# DSC28027 register map
Vendor: Beijing Haawking Technology Co.,Ltd.; File version: 1.0
Registers are 32-bit, read-write, reset 0x0 unless marked. A register's access mark holds for its fields unless they carry their own. Offsets are from the block's base; [hi:lo] are bit positions; lines under a group give offsets from that group; {n}, {i} and the like mark numbered series; 'fields as' and 'values as' point back to an identical list.

## DMAC — Direct Memory Access Controller
Base 0x50000000
0x00 id 64-bit (reset mask 0xFFFFFFFF)
0x08 compver 64-bit (reset mask 0xFFFFFFFF)
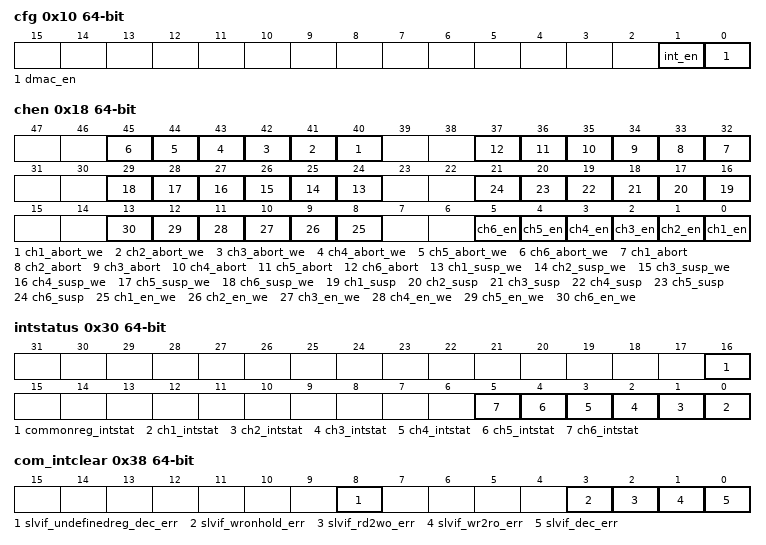
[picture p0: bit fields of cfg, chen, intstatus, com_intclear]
0x10 cfg 64-bit — Configure Register
  [1] int_en — Globally enable interrupt generation
  [0] dmac_en — Enable DMAC
0x18 chen 64-bit (reset mask 0xFFFFFFFF) — Channel Enable Register
  [n+39] ch{n}_abort_we (n=1..6) — Enable write to ch{n}_abort bit
  [n+31] ch{n}_abort (n=1..6) — Abort request channel {n}
  [n+23] ch{n}_susp_we (n=1..6) — Enable write to ch{n}_susp bit
  [n+15] ch{n}_susp (n=1..6) — Suspend request channel {n}
  [n+7] ch{n}_en_we (n=1..6) — Write enable channel {n}
  [n-1] ch{n}_en (n=1..6) — Enable channel {n}
0x30 intstatus 64-bit (reset mask 0xFFFFFFFF) — Interrupt Status Register
  [16] commonreg_intstat — Common register status bit
  [n-1] ch{n}_intstat (n=1..6) — Channel {n} interrupt bit
0x38 com_intclear 64-bit — Common Interrupt Clear Register
  [8] slvif_undefinedreg_dec_err — Clear slvif_undefinedreg_dec_err in com_intstatus
  [3] slvif_wronhold_err — Clear slvif_wronhold_err interrupt in com_intstatus
  [2] slvif_rd2wo_err — Clear slvif_rd2wo_err interrupt in com_intstatus
  [1] slvif_wr2ro_err — Clear slvif_wr2ro_err interrupt in com_intstatus
  [0] slvif_dec_err — Clear slvif_dec_err interrupt in com_intstatus
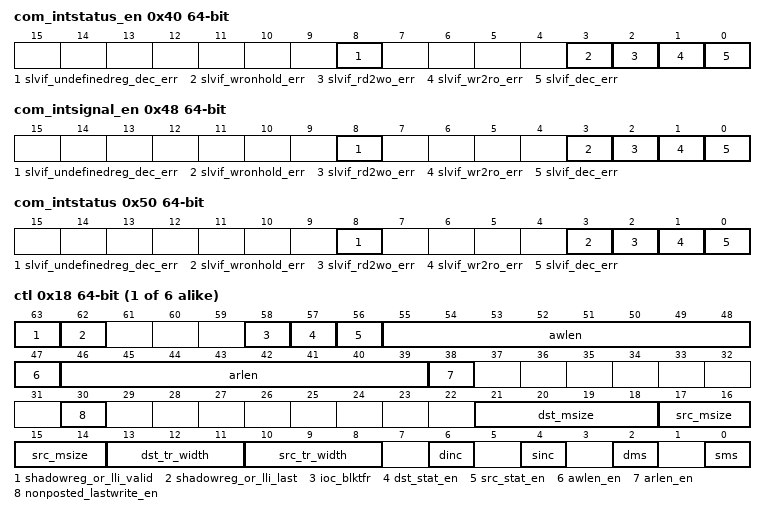
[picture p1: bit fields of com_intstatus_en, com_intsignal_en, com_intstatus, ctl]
0x40 com_intstatus_en 64-bit — Common Interrupt Status Enable Register
  [8] slvif_undefinedreg_dec_err — Slave Interface Undefined Register Decode Error
  [3] slvif_wronhold_err — Slave Interface Common Register Write On Hold Error
  [2] slvif_rd2wo_err — Slave Interface Common Register Read to Write-only Error
  [1] slvif_wr2ro_err — Slave Interface Common Register Write to Read only Error
  [0] slvif_dec_err — Slave Interface Common Register Decode Error
0x48 com_intsignal_en 64-bit — Common Interrupt Signal Enable Register
  fields as com_intstatus_en
0x50 com_intstatus 64-bit — Common Interrupt Status
  fields as com_intstatus_en
0x58 reset 64-bit
  [0] rst — DMAC reset request bit
{0x100+0x100*i} channel[{i}] (i=0..5) group — Channel configuration
  0x00 sar 64-bit (reset mask 0xFFFFFFFF) — SAR Address Register
  0x08 dar 64-bit (reset mask 0xFFFFFFFF) — DAR Address Register
  0x10 block_ts 64-bit — Block Transfer Size Register
    [21:0] block_ts — Block transfer size
  0x18 ctl 64-bit (reset mask 0xFFFFFFFF) — Control Register
    [63] shadowreg_or_lli_valid — last shadow linked list item valid (indicate shadowreg/LLI content is valid)
    [62] shadowreg_or_lli_last — Last shadow linked list item (indicates shadowreg/LLI content is the last one)
    [58] ioc_blktfr — Interrupt completion of block transfer
    [57] dst_stat_en — Destination status enable
    [56] src_stat_en — Source status enable
    [55:48] awlen — Destination burst length
    [47] awlen_en — Destination burst length enable
    [46:39] arlen — Source burst length
    [38] arlen_en — Source burst length enable
    [30] nonposted_lastwrite_en — Non Posted Last Write Enable (posted writes may be used till the end of the block)
    [21:18] dst_msize — Destination burst transaction length
      0=length_1 (1 data item); 1=length_4 (4 data items); 2=length_8 (8 data items); 3=length_16 (16 data items); 4=length_32 (32 data items); 5=length_64 (64 data items); 6=length_128 (128 data items); 7=length_256 (256 data items); 8=length_512 (512 data items); 9=length_1024 (1024 data items)
    [17:14] src_msize — Source burst transaction length
      values as dst_msize
    [13:11] dst_tr_width — Destination transfer width
      0=width_8 (8 bits); 1=width_16 (16 bits); 2=width_32 (32 bits); 3=width_64 (64 bits); 4=width_128 (128 bits); 5=width_256 (256 bits); 6=width_512 (512 bits)
    [10:8] src_tr_width — Source transfer width
      values as dst_tr_width
    [6] dinc — Destination address increment
      0=Increment address; 1=nochange (Don't increment address)
    [4] sinc — Source address increment
      0=Increment address; 1=nochange (Don't increment address)
    [2] dms — Destination master select
      0=axi_master_1; 1=axi_master_2
    [0] sms — Source master select
      0=axi_master_1; 1=axi_master_2
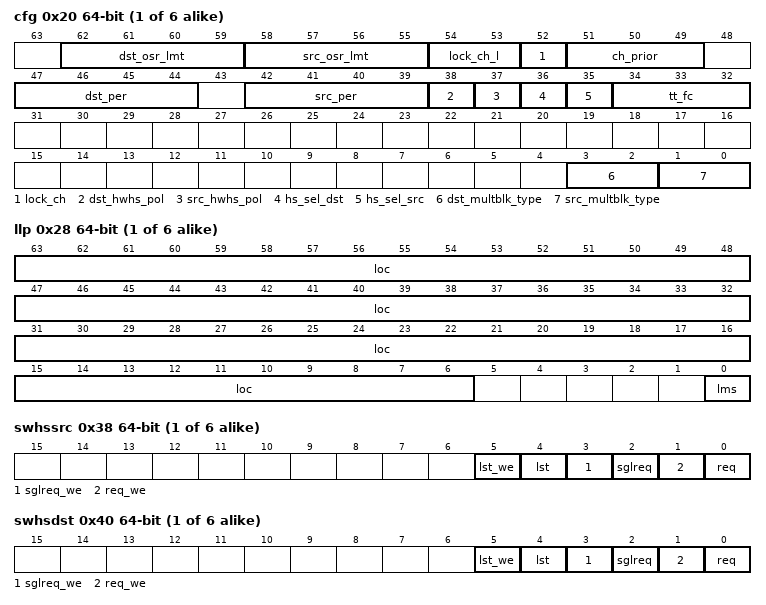
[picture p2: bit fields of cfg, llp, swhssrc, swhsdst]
  0x20 cfg 64-bit (reset mask 0xFFFFFFFF) — Configure Register
    [62:59] dst_osr_lmt — Destination outstanding request limit
    [58:55] src_osr_lmt — Source outstanding request limit
    [54:53] lock_ch_l — Channel lock level
      0=dma_transfer (Duration of channel is locked for entire DMA transfer); 1=block_transfer (Duration of channel is locked for current block transfer); 2=transaction (Duration of channel is locked for current transaction)
    [52] lock_ch — Channel lock bit
    [51:49] ch_prior — Channel priority (7 is highest, 0 is lowest)
    [47:44] dst_per — Assign a hardware handshaking interface to destination of channel
    [42:39] src_per — Assign a hardware handshaking interface to source of channel
    [38] dst_hwhs_pol — Destination hardware handshaking interface polarity
      0=active_high; 1=active_low
    [37] src_hwhs_pol — Source hardware handshaking interface polarity
      0=active_high; 1=active_low
    [36] hs_sel_dst — Destination software or hardware handshaking select
      0=Hardware handshaking is used; 1=Software handshaking is used
    [35] hs_sel_src — Source software or hardware handshaking select
      values as hs_sel_dst
    [34:32] tt_fc — Transfer type and flow control
      0=mem2mem_dma (Transfer memory to memory and flow controller is DMAC); 1=mem2prf_dma (Transfer memory to peripheral and flow controller is DMAC); 2=prf2mem_dma (Transfer peripheral to memory and flow controller is DMAC); 3=prf2prf_dma (Transfer peripheral to peripheral and flow controller is DMAC); 4=prf2mem_prf (Transfer peripheral to memory and flow controller is source peripheral); 5=prf2prf_srcprf (Transfer peripheral to peripheral and flow controller is source peripheral); 6=mem2prf_prf (Transfer memory to peripheral and flow controller is destination peripheral); 7=prf2prf_dstprf (Transfer peripheral to peripheral and flow controller is destination peripheral)
    [3:2] dst_multblk_type — Destination multi-block transfer type
      0=contiguous (Continuous multi-block type); 1=Reload multi-block type; 2=Shadow register based multi-block type; 3=Linked list based multi-block type
    [1:0] src_multblk_type — Source multi-block transfer type
      values as dst_multblk_type
  0x28 llp 64-bit (reset mask 0xFFFFFFFF) — Linked List Pointer register
    [63:6] loc — Starting address memeory of LLI block
    [0] lms — LLI master select
      0=axi_master_1; 1=axi_master_2
  0x30 status 64-bit — Channel Status Register
    [21:0] cmpltd_blk_size — Completed block transfer size
  0x38 swhssrc 64-bit — Channel Software handshake Source Register
    [5] lst_we — Write enable bit for software handshake last request
    [4] lst — Software handshake last request for channel source
    [3] sglreq_we — Write enable bit for software handshake
    [2] sglreq — Software handshake single request for channel source
    [1] req_we — Write enable bit for software handshake request
    [0] req — Software handshake request for channel source
  0x40 swhsdst 64-bit — Channel Software handshake Destination Register
    [5] lst_we — Write enable bit for software handshake last request
    [4] lst — Software handshake last request for channel destination
    [3] sglreq_we — Write enable bit for software handshake
    [2] sglreq — Software handshake single request for channel destination
    [1] req_we — Write enable bit for software handshake request
    [0] req — Software handshake request for channel destination
  0x48 blk_tfr 64-bit — Channel Block Transfer Resume Request Register
    [0] resumereq — Block transfer resume request
  0x50 axi_id 64-bit (reset mask 0xFFFFFFFF) — Channel AXI ID Register
  0x58 axi_qos 64-bit (reset mask 0xFFFFFFFF)
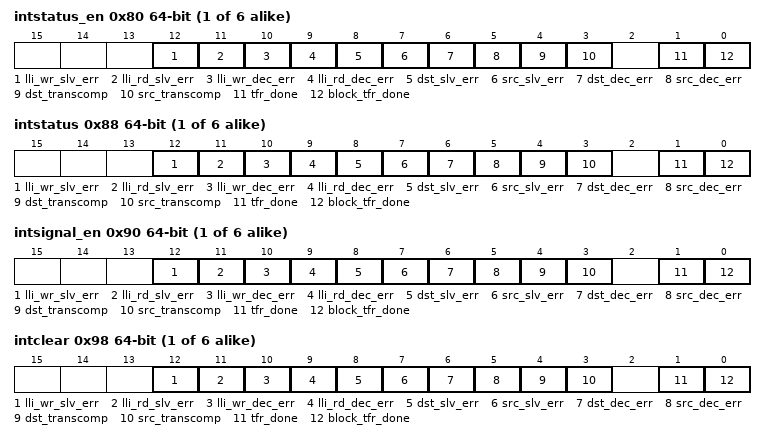
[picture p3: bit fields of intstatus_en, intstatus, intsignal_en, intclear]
  0x80 intstatus_en 64-bit — Interrupt Status Enable Register
    [12] lli_wr_slv_err — LLI WRITE Slave Error
    [11] lli_rd_slv_err — LLI Read Slave Error
    [10] lli_wr_dec_err — LLI WRITE Decode Error
    [9] lli_rd_dec_err — LLI Read Decode Error Status Enable
    [8] dst_slv_err — Destination Slave Error
    [7] src_slv_err — Source Slave Error
    [6] dst_dec_err — Destination Decode Error
    [5] src_dec_err — Source Decode Error
    [4] dst_transcomp — Destination transaction complete
    [3] src_transcomp — Source transaction complete
    [1] tfr_done — Transfer done
    [0] block_tfr_done — Block transfer done
  0x88 intstatus 64-bit — Channel Interrupt Status Register
    fields as channel[0].intstatus_en
  0x90 intsignal_en 64-bit — Interrupt Signal Enable Register
    fields as channel[0].intstatus_en
  0x98 intclear 64-bit — Interrupt Clear Register
    fields as channel[0].intstatus_en
  0xF8 _reserved 64-bit (reset mask 0xFFFFFFFF) — Padding to make structure size 256 bytes so that channels[] is an array
